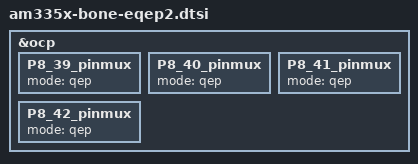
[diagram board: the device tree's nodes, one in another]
/*
 * Copyright (C) 2013 Nathaniel R. Lewis - http://nathanielrlewis.com/
 *
 * This program is free software; you can redistribute it and/or modify
 * it under the terms of the GNU General Public License version 2 as
 * published by the Free Software Foundation.
 * 
 * Enable eQEP2 on the Beaglebone White and Black
 */

#include "am335x-eqep2.dtsi"

&ocp {
	/* eQEP2_index */
	P8_39_pinmux {
		mode = "qep";
	};

	/* eQEP2_strobe */
	P8_40_pinmux {
		mode = "qep";
	};

	/* eQEP2A_in */
	P8_41_pinmux {
		mode = "qep";
	};

	/* eQEP2B_in */
	P8_42_pinmux {
		mode = "qep";
	};
};

